# nrf9230_cellrf register map
Vendor: Nordic Semiconductor; Series: nRF92; File version: 1
CPU: CM0 r0p0, little endian, no MPU, no FPU, 2 interrupt priority bits, 33 interrupts
Registers are 32-bit, read-write, reset 0x0 unless marked. A register's access mark holds for its fields unless they carry their own. Offsets are from the block's base; [hi:lo] are bit positions; lines under a group give offsets from that group; {n}, {i} and the like mark numbered series; 'fields as' and 'values as' point back to an identical list.

## DPPIC — Distributed programmable peripheral interconnect controller
Base 0x46150000
Same registers: GLOBAL_DPPIC120 0x5F8E1000, GLOBAL_DPPIC130 0x5F922000, GLOBAL_DPPIC131 0x5F981000, GLOBAL_DPPIC132 0x5F991000, GLOBAL_DPPIC133 0x5F9A1000, GLOBAL_DPPIC134 0x5F9B1000, GLOBAL_DPPIC135 0x5F9C1000, GLOBAL_DPPIC136 0x5F9D1000
{0x0+8i} TASKS_CHG[{i}] (i=0..3) group — Channel group tasks
  0x00 EN wo — Description cluster: Enable channel group n
    [0] EN — Enable channel group n
      1=Trigger task
  0x04 DIS wo — Description cluster: Disable channel group n
    [0] DIS — Disable channel group n
      1=Trigger task
{0x80+8i} SUBSCRIBE_CHG[{i}] (i=0..3) group — Subscribe configuration for tasks
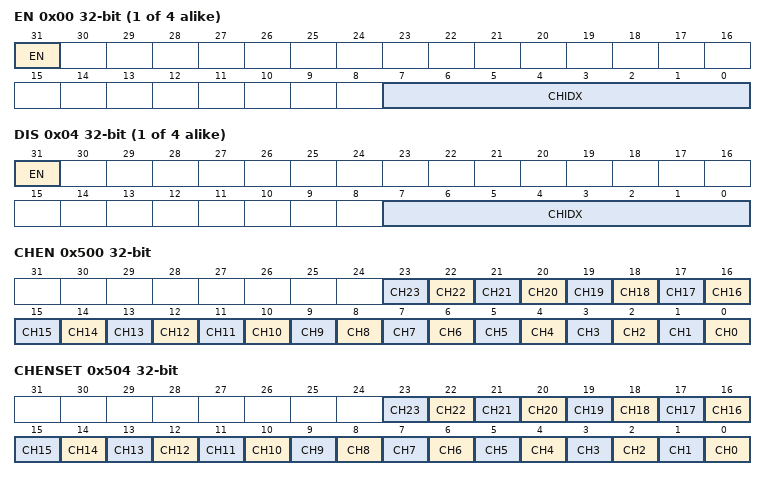
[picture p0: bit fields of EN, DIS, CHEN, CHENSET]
  0x00 EN — Description cluster: Subscribe configuration for task CHG[n].EN
    [31] EN
      0=Disabled (Disable subscription); 1=Enabled (Enable subscription)
    [7:0] CHIDX — DPPI channel that task CHG[n].EN will subscribe to
  0x04 DIS — Description cluster: Subscribe configuration for task CHG[n].DIS
    [31] EN
      values as SUBSCRIBE_CHG[0].EN.EN
    [7:0] CHIDX — DPPI channel that task CHG[n].DIS will subscribe to
0x500 CHEN — Channel enable register
  [all] fields
    0=Disabled (Disable channel); 1=Enabled (Enable channel)
  [n] CH{n} (n=0..23) — Enable or disable channel {n}
0x504 CHENSET write-1-sets — Channel enable set register
  [all] fields
    on read: 0=Disabled (Read: Channel disabled); 1=Enabled (Read: Channel enabled) | on write: 1=Set (Write: Enable channel)
  [n] CH{n} (n=0..23) — Channel {n} enable set register. Writing 0 has no effect.
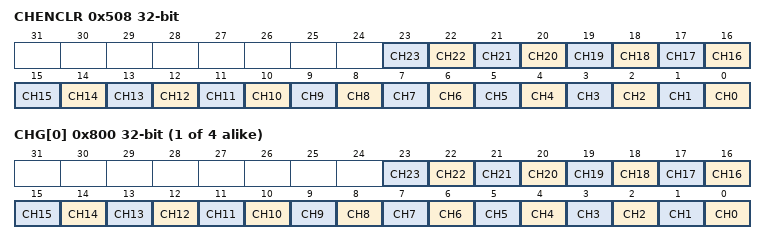
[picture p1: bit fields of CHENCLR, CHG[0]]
0x508 CHENCLR write-1-clears — Channel enable clear register
  [all] fields
    on read: 0=Disabled (Read: Channel disabled); 1=Enabled (Read: Channel enabled) | on write: 1=Clear (Write: Disable channel)
  [n] CH{n} (n=0..23) — Channel {n} enable clear register. Writing 0 has no effect.
{0x800+4i} CHG[{i}] (i=0..3) — Description collection: Channel group n Note: Writes to this register are ignored if either SUBSCRIBE_CHG[n].EN or SUBSCRIBE_CHG[n].DIS is enabled
  [all] fields
    0=Excluded; 1=Included
  [n] CH{n} (n=0..23) — Include or exclude channel {n}

## GLOBAL_STMDATA — System Trace Macrocell data buffer
Base 0xA0000000
{0x0+0x1000000*i} DOMAIN[{i}] (i=0..15) group — Unspecified
  {0x0+j} DATA[{j}] (j=0..16777215) 8-bit — Description collection: STM extended stimulus port data buffer area for domain n. NonSecure writes to this region generates trace packets with id n+96. Secure writes to this region generates trace packets with id n+32.

## GLOBAL_TDDCONF — TDDCONF
Base 0xBF001000
0x400 SYSPWRUPREQ — System power-up request
  [0] ACTIVE — Activate power-up request
    0=NotActive (Power-up request not active); 1=Active (Power-up request active)
0x404 DBGPWRUPREQ — Debug power-up request
  fields as SYSPWRUPREQ
0x408 TRACEPORTSPEED — Trace port trace clock speed
  [1:0] SPEED — Trace clock speed
    0=Speed100MHz; 1=Speed50MHz; 2=Speed25MHz; 3=Speed12500KHz (Speed 12.5MHz)
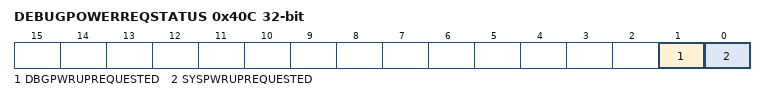
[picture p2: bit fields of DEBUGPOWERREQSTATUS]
0x40C DEBUGPOWERREQSTATUS ro — Combined effective system status of both SWJ-DP and TDDCONF registers originated power requests
  [1] DBGPWRUPREQUESTED — Debug domain powerup request status
    0=NoPowerReq (Power not requested); 1=Power requested
  [0] SYSPWRUPREQUESTED — System powerup request status
    0=NoPowerReq (Power not requested); 1=Power requested

## GLOBAL_TSGEN — Timestamp generator
Base 0xBF041000
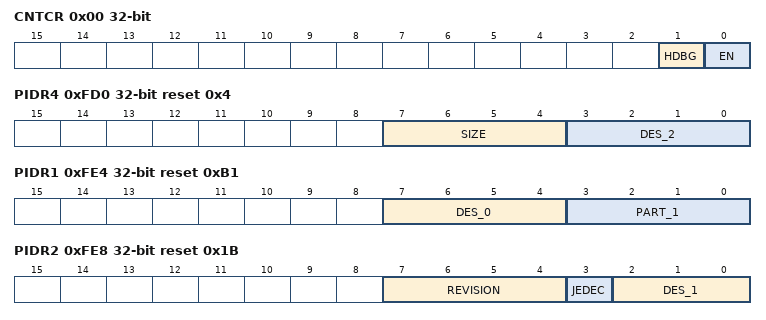
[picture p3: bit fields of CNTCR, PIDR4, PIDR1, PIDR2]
0x00 CNTCR — Counter Control Register
  [1] HDBG — Halt on Debug
    0=Disabled (Do not halt on debug, HLTDBG signal into the counter has no effect.); 1=Enabled (Halt on debug, when HLTDBG is driven HIGH, the count value is held static.)
  [0] EN — Counter enable
    0=Disabled (Unspecified); 1=Enabled (Unspecified)
0x04 CNTSR ro — Counter Status Register
  [1] DBGH — Debug halted
0x08 CNTCVL — Current Counter Value Lower register
  [31:0] CNTCVL_L_32 — Current value of Counter, lower 32 bits
0x0C CNTCVU — Current Counter Value Upper register
  [31:0] CNTCVU_U_32 — Current value of Counter, upper 32 bits
0x20 CNTFID0 — Base Frequency ID
  [31:0] FREQ — Frequency in number of ticks per second (up to 4 GHz)
0xFD0 PIDR4 ro reset 0x4 — Peripheral ID4 Register
  [7:4] SIZE — This is a 4-bit value that indicates the total contiguous size of the memory window used by this component in powers of 2 from the standard 4KB. If a component only requires the standard 4KB, this must read as 0x0, 4KB only. For 8KB set to 0x1, for 16KB set to 0x2, for 32KB set to 0x3, and so on.
  [3:0] DES_2 — JEDEC continuation code indicating the designer of the component, together with the identity code.
0xFE0 PIDR0 ro reset 0x1 — Peripheral ID0 Register
  [7:0] PART_0 — Bits [7:0] of the component part number. This is selected by the designer of the component.
0xFE4 PIDR1 ro reset 0xB1 — Peripheral ID1 Register
  [7:4] DES_0 — Bits [3:0] of the JEDEC identity code indicating the designer of the component, together with the continuation code.
  [3:0] PART_1 — Bits [11:8] of the component part number. This is selected by the designer of the component.
0xFE8 PIDR2 ro reset 0x1B — Peripheral ID2 Register
  [7:4] REVISION — The Revision field is an incremental value starting at 0x0 for the first design of this component. This only increases by 1 for both major and minor revisions and is used as a look-up to establish the exact major and minor revision.
  [3] JEDEC — Always set. Indicates that a JEDEC assigned value is used.
  [2:0] DES_1 — Bits [6:4] of the JEDEC identity code indicating the designer of the component, together with the continuation code.
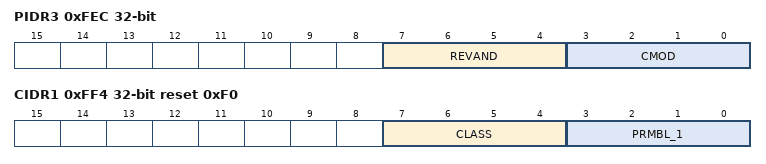
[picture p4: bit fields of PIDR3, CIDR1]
0xFEC PIDR3 ro — Peripheral ID3 Register
  [7:4] REVAND — This field indicates minor errata fixes specific to this design, for example metal fixes after implementation. In most cases this field is zero. It is recommended that component designers ensure this field can be changed by a metal fix if required, for example by driving it from registers that reset to zero.
  [3:0] CMOD — Where the component is reusable IP, this value indicates if the customer has modified the behavior of the component. In most cases this field is zero.
0xFF0 CIDR0 ro reset 0xD — Component ID0 Register
  [7:0] PRMBL_0 — Contains bits[7:0] of the component identification code.
0xFF4 CIDR1 ro reset 0xF0 — Component ID1 Register
  [7:4] CLASS — Class of the component, for example, ROM table or CoreSight component.
  [3:0] PRMBL_1 — Contains bits[11:8] of the component identification code.
0xFF8 CIDR2 ro reset 0x5 — Component ID2 Register
  [7:0] PRMBL_2 — Contains bits[23:16] of the component identification code.
0xFFC CIDR3 ro reset 0xB1 — Component ID3 Register
  [7:0] PRMBL_3 — Contains bits[31:24] of the component identification code.

## Notices in the file
Copyright (c) 2010 - 2024, Nordic Semiconductor ASA
All rights reserved.
Redistribution and use in source and binary forms, with or without modification,
are permitted provided that the following conditions are met:
1. Redistributions of source code must retain the above copyright notice, this
list of conditions and the following disclaimer.
2. Redistributions in binary form, except as embedded into a Nordic
Semiconductor ASA integrated circuit in a product or a software update for
such product, must reproduce the above copyright notice, this list of
conditions and the following disclaimer in the documentation and/or other
materials provided with the distribution.
3. Neither the name of Nordic Semiconductor ASA nor the names of its
contributors may be used to endorse or promote products derived from this
software without specific prior written permission.
4. This software, with or without modification, must only be used with a
Nordic Semiconductor ASA integrated circuit.
5. Any software provided in binary form under this license must not be reverse
engineered, decompiled, modified and/or disassembled.
THIS SOFTWARE IS PROVIDED BY NORDIC SEMICONDUCTOR ASA "AS IS" AND ANY EXPRESS
OR IMPLIED WARRANTIES, INCLUDING, BUT NOT LIMITED TO, THE IMPLIED WARRANTIES
OF MERCHANTABILITY, NONINFRINGEMENT, AND FITNESS FOR A PARTICULAR PURPOSE ARE
DISCLAIMED. IN NO EVENT SHALL NORDIC SEMICONDUCTOR ASA OR CONTRIBUTORS BE
LIABLE FOR ANY DIRECT, INDIRECT, INCIDENTAL, SPECIAL, EXEMPLARY, OR
CONSEQUENTIAL DAMAGES (INCLUDING, BUT NOT LIMITED TO, PROCUREMENT OF SUBSTITUTE
GOODS OR SERVICES; LOSS OF USE, DATA, OR PROFITS; OR BUSINESS INTERRUPTION)
HOWEVER CAUSED AND ON ANY THEORY OF LIABILITY, WHETHER IN CONTRACT, STRICT
LIABILITY, OR TORT (INCLUDING NEGLIGENCE OR OTHERWISE) ARISING IN ANY WAY OUT
OF THE USE OF THIS SOFTWARE, EVEN IF ADVISED OF THE POSSIBILITY OF SUCH DAMAGE.
